# MKM34Z7 register map
Vendor: Freescale Semiconductor, Inc.; Series: Kinetis_M; File version: 1.6
CPU: CM0PLUS r0p0, little endian, no MPU, no FPU, VTOR, 2 interrupt priority bits
Registers are 32-bit, read-write, reset 0x0 unless marked. A register's access mark holds for its fields unless they carry their own. Offsets are from the block's base; [hi:lo] are bit positions; {n}, {i} and the like mark numbered series; 'fields as' and 'values as' point back to an identical list.

## FTFA_FlashConfig — Flash configuration field
Base 0x00000400; register names take the prefix NV_
0x00 BACKKEY3 8-bit ro reset 0xFF — Backdoor Comparison Key 3.
  [7:0] KEY — Backdoor Comparison Key.
0x01 BACKKEY2 8-bit ro reset 0xFF — Backdoor Comparison Key 2.
  [7:0] KEY — Backdoor Comparison Key.
0x02 BACKKEY1 8-bit ro reset 0xFF — Backdoor Comparison Key 1.
  [7:0] KEY — Backdoor Comparison Key.
0x03 BACKKEY0 8-bit ro reset 0xFF — Backdoor Comparison Key 0.
  [7:0] KEY — Backdoor Comparison Key.
0x04 BACKKEY7 8-bit ro reset 0xFF — Backdoor Comparison Key 7.
  [7:0] KEY — Backdoor Comparison Key.
0x05 BACKKEY6 8-bit ro reset 0xFF — Backdoor Comparison Key 6.
  [7:0] KEY — Backdoor Comparison Key.
0x06 BACKKEY5 8-bit ro reset 0xFF — Backdoor Comparison Key 5.
  [7:0] KEY — Backdoor Comparison Key.
0x07 BACKKEY4 8-bit ro reset 0xFF — Backdoor Comparison Key 4.
  [7:0] KEY — Backdoor Comparison Key.
0x08 FPROT3 8-bit ro reset 0xFF — Non-volatile P-Flash Protection 1 - Low Register
  [7:0] PROT — P-Flash Region Protect
0x09 FPROT2 8-bit ro reset 0xFF — Non-volatile P-Flash Protection 1 - High Register
  [7:0] PROT — P-Flash Region Protect
0x0A FPROT1 8-bit ro reset 0xFF — Non-volatile P-Flash Protection 0 - Low Register
  [7:0] PROT — P-Flash Region Protect
0x0B FPROT0 8-bit ro reset 0xFF — Non-volatile P-Flash Protection 0 - High Register
  [7:0] PROT — P-Flash Region Protect
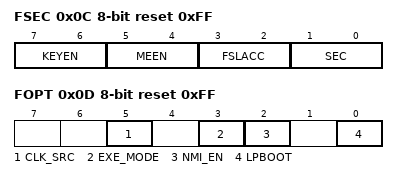
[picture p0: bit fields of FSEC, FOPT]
0x0C FSEC 8-bit ro reset 0xFF — Non-volatile Flash Security Register
  [7:6] KEYEN — Backdoor Key Security Enable
    2=Backdoor key access enabled; 3=Backdoor key access disabled
  [5:4] MEEN
    2=Mass erase is disabled; 3=Mass erase is enabled
  [3:2] FSLACC — Freescale Failure Analysis Access Code
    2=Freescale factory access denied; 3=Freescale factory access granted
  [1:0] SEC — Flash Security
    2=MCU security status is unsecure; 3=MCU security status is secure
0x0D FOPT 8-bit ro reset 0xFF — Non-volatile Flash Option Register
  [5] CLK_SRC
    0=Externally supplied clock used by Flash; 1=Internal clock source used by Flash
  [3] EXE_MODE
    0=Execution Mode is RUN Mode; 1=Execution Mode is VLPR Mode
  [2] NMI_EN
    0=NMI interrupts are always blocked; 1=NMI_b pin/interrupts reset default to enabled
  [0] LPBOOT
    0=Low-power boot; 1=Normal boot

## AIPS — AIPS-Lite Bridge
Base 0x40000000; register names take the prefix AIPS_
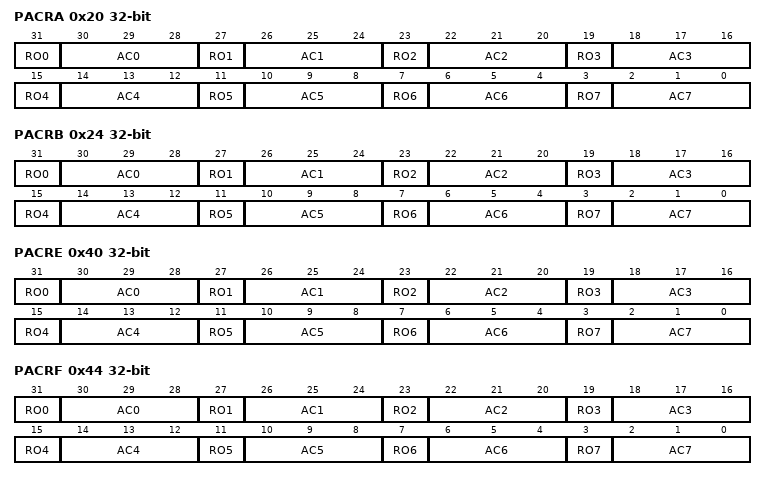
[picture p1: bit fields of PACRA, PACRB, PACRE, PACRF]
0x20 PACRA — Peripheral Access Control Register
  [31-4n] RO{n} (n=0..7) — Read Only
    0=Writes to corresponding AC field are allowed; 1=Writes to corresponding AC field are ignored
  [30-4n:28-4n] AC{n} (n=0..7) — Attribute Check
0x24 PACRB — Peripheral Access Control Register
  fields as PACRA
0x40 PACRE — Peripheral Access Control Register
  fields as PACRA
0x44 PACRF — Peripheral Access Control Register
  fields as PACRA
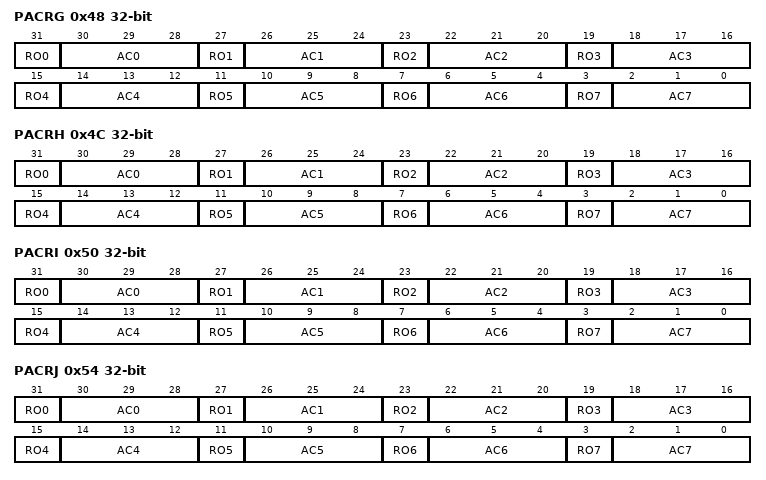
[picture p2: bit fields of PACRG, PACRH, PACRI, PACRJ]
0x48 PACRG — Peripheral Access Control Register
  fields as PACRA
0x4C PACRH — Peripheral Access Control Register
  fields as PACRA
0x50 PACRI — Peripheral Access Control Register
  fields as PACRA
0x54 PACRJ — Peripheral Access Control Register
  fields as PACRA
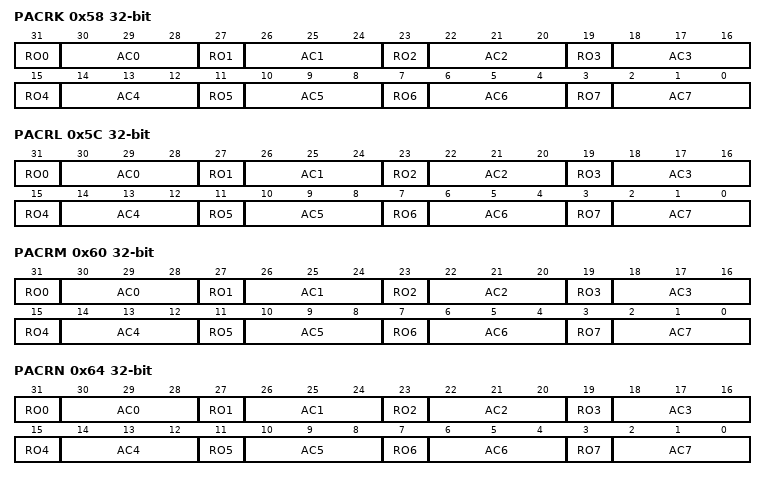
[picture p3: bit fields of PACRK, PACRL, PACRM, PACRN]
0x58 PACRK — Peripheral Access Control Register
  fields as PACRA
0x5C PACRL — Peripheral Access Control Register
  fields as PACRA
0x60 PACRM — Peripheral Access Control Register
  fields as PACRA
0x64 PACRN — Peripheral Access Control Register
  fields as PACRA
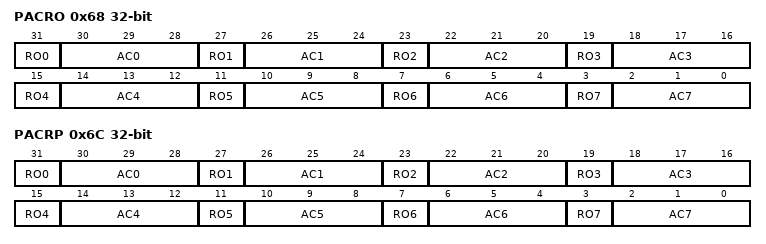
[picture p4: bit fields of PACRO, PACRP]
0x68 PACRO — Peripheral Access Control Register
  fields as PACRA
0x6C PACRP — Peripheral Access Control Register
  fields as PACRA

## FTFA — Flash Memory Interface
Base 0x40020000; register names take the prefix FTFA_
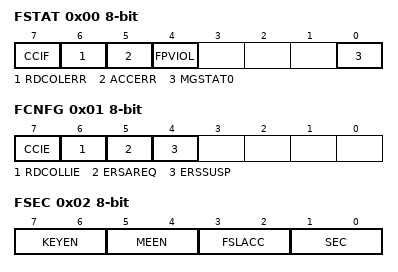
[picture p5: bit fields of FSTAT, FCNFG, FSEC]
0x00 FSTAT 8-bit — Flash Status Register
  [7] CCIF — Command Complete Interrupt Flag
    0=Flash command in progress; 1=Flash command has completed
  [6] RDCOLERR — Flash Read Collision Error Flag
    0=No collision error detected; 1=Collision error detected
  [5] ACCERR — Flash Access Error Flag
    0=No access error detected; 1=Access error detected
  [4] FPVIOL — Flash Protection Violation Flag
    0=No protection violation detected; 1=Protection violation detected
  [0] MGSTAT0 ro — Memory Controller Command Completion Status Flag
0x01 FCNFG 8-bit — Flash Configuration Register
  [7] CCIE — Command Complete Interrupt Enable
    0=Command complete interrupt disabled; 1=Command complete interrupt enabled. An interrupt request is generated whenever the FSTAT[CCIF] flag is set.
  [6] RDCOLLIE — Read Collision Error Interrupt Enable
    0=Read collision error interrupt disabled; 1=Read collision error interrupt enabled. An interrupt request is generated whenever a flash memory read collision error is detected (see the description of FSTAT[RDCOLERR]).
  [5] ERSAREQ ro — Erase All Request
    0=No request or request complete; 1=Request to: run the Erase All Blocks command, verify the erased state, program the security byte in the Flash Configuration Field to the unsecure state, and release MCU security by setting the FSEC[SEC] field to the unsecure state
  [4] ERSSUSP — Erase Suspend
    0=No suspend requested; 1=Suspend the current Erase Flash Sector command execution
0x02 FSEC 8-bit ro reset not defined — Flash Security Register
  [7:6] KEYEN — Backdoor Key Security Enable
    0=Backdoor key access disabled; 1=Backdoor key access disabled (preferred KEYEN state to disable backdoor key access); 2=Backdoor key access enabled; 3=Backdoor key access disabled
  [5:4] MEEN — Mass Erase Enable
    0=Mass erase is enabled; 1=Mass erase is enabled; 2=Mass erase is disabled; 3=Mass erase is enabled
  [3:2] FSLACC — Freescale Failure Analysis Access Code
    0=Freescale factory access granted; 1=Freescale factory access denied; 2=Freescale factory access denied; 3=Freescale factory access granted
  [1:0] SEC — Flash Security
    0=MCU security status is secure; 1=MCU security status is secure; 2=MCU security status is unsecure. (The standard shipping condition of the flash memory module is unsecure.); 3=MCU security status is secure
0x03 FOPT 8-bit ro reset not defined — Flash Option Register
  [7:0] OPT — Nonvolatile Option
0x04 FCCOB{x} (x=3,2,1,0,7,6,5,4,B,A,9,8; step 0x1) 8-bit — Flash Common Command Object Registers
  [7:0] CCOBn — The FCCOB register provides a command code and relevant parameters to the memory controller
0x10 FPROT{x} (x=3,2,1,0; step 0x1) 8-bit reset not defined — Program Flash Protection Registers
  [7:0] PROT — Program Flash Region Protect
    0=Program flash region is protected; 1=Program flash region is not protected
